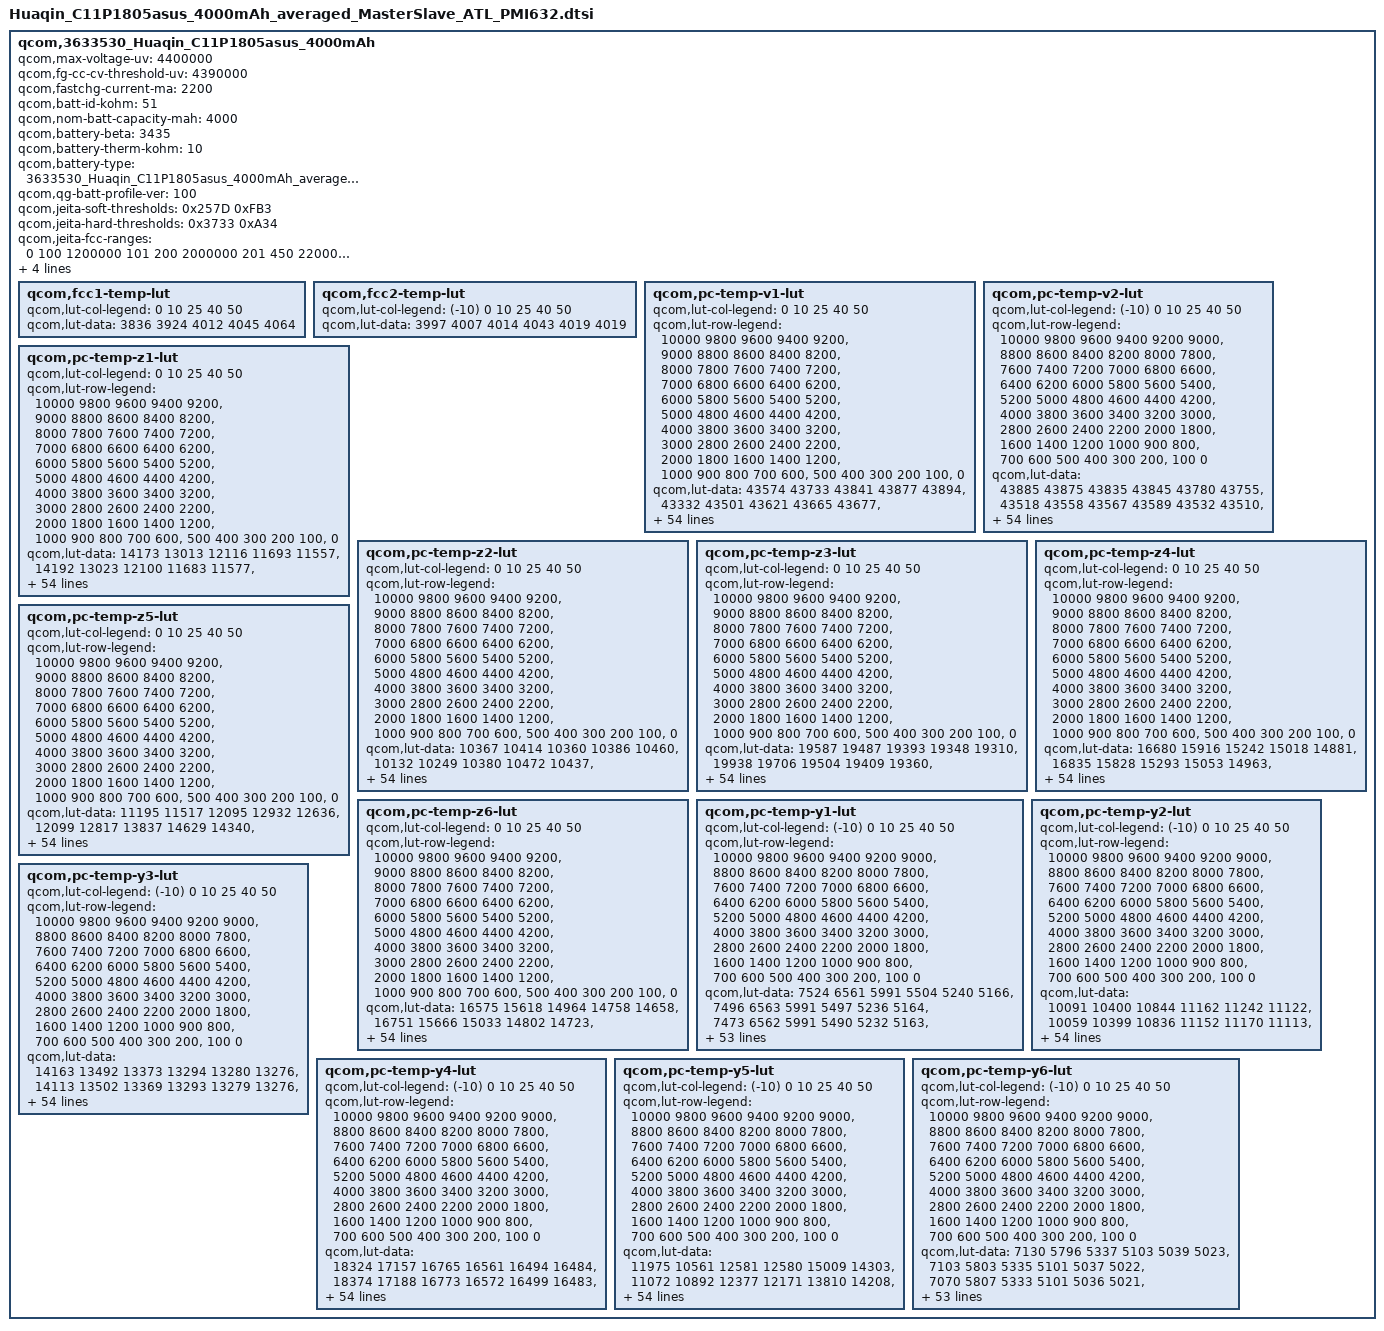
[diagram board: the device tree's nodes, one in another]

qcom,3633530_Huaqin_C11P1805asus_4000mAh {
    /* 3633530_Huaqin_C11P1805asus_4000mAh_averaged_MasterSlave_Aug22nd2018 */
    qcom,max-voltage-uv = <4400000>;
    qcom,fg-cc-cv-threshold-uv = <4390000>;
//huaqin add by tangqingyong for ZQL1830-194 jeita & step charge at 20180823 start
    qcom,fastchg-current-ma = <2200>;
//huaqin add by tangqingyong for ZQL1830-194 jeita & step charge at 20180823 end
    qcom,batt-id-kohm = <51>;
    qcom,nom-batt-capacity-mah = <4000>;
    qcom,battery-beta = <3435>;
    qcom,battery-therm-kohm = <10>;
    qcom,battery-type = "3633530_Huaqin_C11P1805asus_4000mAh_averaged_MasterSlave_Aug22nd2018";
    qcom,qg-batt-profile-ver = <100>;
//huaqin add by tangqingyong for ZQL1830-412 NTC batt-therm config start
    /* COOL = 15 DegC, WARM = 45 DegC */
    qcom,jeita-soft-thresholds = <0x257D 0xFB3>;
    /* COLD = 0 DegC, HOT = 60 DegC */
    qcom,jeita-hard-thresholds = <0x3733 0xA34>;
//huaqin add by tangqingyong for ZQL1830-412 NTC batt-therm config end
//huaqin add by tangqingyong for ZQL1830-194 jeita & step charge at 20180823 start
       qcom,jeita-fcc-ranges = <0   100  1200000
                               101  200  2000000
                               201  450  2200000
                               451  600  1400000>;
       qcom,jeita-fv-ranges = <0   100  4400000
                               101 200  4400000
                               201 450  4400000
                               451 600  4100000>;

       qcom,step-chg-ranges = <3500000  4250000  2200000
                               4251000  4400000  2000000>;
//huaqin add by tangqingyong for ZQL1830-194 jeita & step charge at 20180823 end

	qcom,fcc1-temp-lut {
		qcom,lut-col-legend = <0 10 25 40 50>;
		qcom,lut-data = <3836 3924 4012 4045 4064>;
	};

	qcom,fcc2-temp-lut {
		qcom,lut-col-legend = <(-10) 0 10 25 40 50>;
		qcom,lut-data = <3997 4007 4014 4043 4019 4019>;
	};

	qcom,pc-temp-v1-lut {
		qcom,lut-col-legend = <0 10 25 40 50>;
		qcom,lut-row-legend = <10000 9800 9600 9400 9200>,
			<9000 8800 8600 8400 8200>,
			<8000 7800 7600 7400 7200>,
			<7000 6800 6600 6400 6200>,
			<6000 5800 5600 5400 5200>,
			<5000 4800 4600 4400 4200>,
			<4000 3800 3600 3400 3200>,
			<3000 2800 2600 2400 2200>,
			<2000 1800 1600 1400 1200>,
			<1000 900 800 700 600>,
			<500 400 300 200 100>,
			<0>;
		qcom,lut-data = <43574 43733 43841 43877 43894>,
			<43332 43501 43621 43665 43677>,
			<43092 43267 43393 43447 43460>,
			<42855 43030 43162 43226 43242>,
			<42623 42795 42929 42996 43016>,
			<42396 42560 42694 42761 42783>,
			<42173 42328 42459 42528 42550>,
			<41954 42101 42224 42294 42316>,
			<41739 41879 41993 42064 42084>,
			<41531 41662 41766 41834 41857>,
			<41329 41449 41544 41607 41632>,
			<41134 41241 41329 41386 41410>,
			<40952 41044 41119 41168 41189>,
			<40767 40860 40914 40959 40975>,
			<40549 40674 40710 40756 40769>,
			<40290 40459 40509 40557 40571>,
			<40060 40224 40305 40360 40377>,
			<39899 40025 40109 40166 40188>,
			<39767 39877 39940 39988 40008>,
			<39637 39743 39805 39836 39847>,
			<39505 39591 39656 39685 39689>,
			<39372 39426 39431 39486 39497>,
			<39232 39249 39166 39243 39263>,
			<39086 39038 38979 39038 39053>,
			<38945 38831 38851 38884 38892>,
			<38810 38704 38740 38753 38754>,
			<38684 38624 38634 38636 38633>,
			<38584 38555 38536 38531 38528>,
			<38502 38481 38447 38436 38432>,
			<38433 38410 38365 38347 38338>,
			<38375 38348 38294 38267 38254>,
			<38324 38291 38233 38195 38178>,
			<38282 38241 38181 38129 38110>,
			<38249 38200 38133 38070 38047>,
			<38219 38166 38092 38023 37995>,
			<38189 38130 38051 37975 37943>,
			<38159 38098 38012 37921 37879>,
			<38120 38059 37971 37862 37804>,
			<38055 37994 37909 37791 37724>,
			<37968 37894 37812 37704 37638>,
			<37867 37784 37698 37604 37540>,
			<37740 37664 37580 37488 37421>,
			<37596 37528 37446 37353 37282>,
			<37432 37361 37285 37195 37125>,
			<37314 37230 37148 37061 36997>,
			<37224 37148 37070 36981 36924>,
			<37198 37126 37048 36964 36903>,
			<37174 37104 37030 36948 36888>,
			<37148 37086 37016 36929 36869>,
			<37076 37017 36935 36839 36747>,
			<36777 36707 36620 36519 36411>,
			<36307 36244 36161 36061 35947>,
			<35703 35642 35560 35466 35346>,
			<34872 34814 34734 34647 34514>,
			<33541 33493 33421 33359 33194>,
			<30000 30000 30000 30000 30000>;
	};

	qcom,pc-temp-v2-lut {
		qcom,lut-col-legend = <(-10) 0 10 25 40 50>;
		qcom,lut-row-legend = <10000 9800 9600 9400 9200 9000>,
			<8800 8600 8400 8200 8000 7800>,
			<7600 7400 7200 7000 6800 6600>,
			<6400 6200 6000 5800 5600 5400>,
			<5200 5000 4800 4600 4400 4200>,
			<4000 3800 3600 3400 3200 3000>,
			<2800 2600 2400 2200 2000 1800>,
			<1600 1400 1200 1000 900 800>,
			<700 600 500 400 300 200>,
			<100 0>;
		qcom,lut-data = <43885 43875 43835 43845 43780 43755>,
			<43518 43558 43567 43589 43532 43510>,
			<43181 43263 43307 43339 43289 43271>,
			<42878 42991 43057 43098 43051 43035>,
			<42602 42743 42818 42864 42819 42805>,
			<42355 42502 42582 42632 42589 42576>,
			<42150 42259 42348 42399 42358 42344>,
			<41958 42021 42117 42168 42128 42113>,
			<41715 41789 41890 41938 41900 41885>,
			<41400 41562 41667 41710 41673 41658>,
			<41166 41346 41447 41484 41450 41435>,
			<41073 41150 41232 41260 41229 41218>,
			<41001 40962 41020 41040 41012 41004>,
			<40801 40765 40820 40835 40807 40797>,
			<40290 40560 40630 40641 40612 40595>,
			<39838 40335 40430 40442 40417 40399>,
			<39616 40048 40205 40226 40213 40207>,
			<39446 39751 39969 40017 40015 40023>,
			<39273 39530 39748 39843 39841 39850>,
			<39100 39361 39534 39690 39691 39690>,
			<38932 39197 39332 39511 39520 39511>,
			<38763 39019 39136 39269 39289 39279>,
			<38603 38845 38955 39028 39048 39040>,
			<38470 38693 38800 38849 38866 38859>,
			<38356 38558 38663 38699 38715 38711>,
			<38264 38433 38539 38571 38586 38583>,
			<38192 38313 38426 38459 38474 38471>,
			<38130 38202 38322 38359 38373 38369>,
			<38072 38109 38227 38265 38279 38275>,
			<38018 38028 38138 38179 38191 38186>,
			<37965 37964 38057 38099 38112 38107>,
			<37912 37915 37979 38023 38041 38035>,
			<37860 37872 37907 37951 37974 37966>,
			<37806 37829 37846 37886 37906 37896>,
			<37754 37787 37795 37826 37839 37825>,
			<37699 37741 37746 37762 37761 37739>,
			<37638 37687 37700 37694 37666 37626>,
			<37572 37628 37654 37622 37566 37508>,
			<37499 37563 37598 37551 37479 37412>,
			<37420 37492 37532 37476 37399 37328>,
			<37338 37411 37452 37390 37313 37238>,
			<37255 37310 37340 37288 37214 37136>,
			<37171 37192 37209 37165 37097 37016>,
			<37087 37059 37060 37016 36947 36868>,
			<36995 36941 36947 36910 36845 36785>,
			<36896 36862 36889 36880 36820 36757>,
			<36843 36822 36875 36866 36805 36744>,
			<36779 36779 36846 36844 36783 36719>,
			<36696 36719 36802 36792 36744 36672>,
			<36552 36599 36668 36612 36613 36462>,
			<36285 36312 36317 36213 36240 36045>,
			<35851 35825 35780 35648 35724 35497>,
			<35215 35160 35073 34914 35049 34778>,
			<34285 34229 34083 33807 34101 33741>,
			<32726 32699 32527 32534 32677 32295>,
			<26800 26533 26564 26630 28170 27182>;
	};

	qcom,pc-temp-z1-lut {
		qcom,lut-col-legend = <0 10 25 40 50>;
		qcom,lut-row-legend = <10000 9800 9600 9400 9200>,
			<9000 8800 8600 8400 8200>,
			<8000 7800 7600 7400 7200>,
			<7000 6800 6600 6400 6200>,
			<6000 5800 5600 5400 5200>,
			<5000 4800 4600 4400 4200>,
			<4000 3800 3600 3400 3200>,
			<3000 2800 2600 2400 2200>,
			<2000 1800 1600 1400 1200>,
			<1000 900 800 700 600>,
			<500 400 300 200 100>,
			<0>;
		qcom,lut-data = <14173 13013 12116 11693 11557>,
			<14192 13023 12100 11683 11577>,
			<14157 13023 12091 11679 11572>,
			<14143 13011 12083 11677 11569>,
			<14171 13000 12075 11673 11567>,
			<14210 12995 12067 11669 11565>,
			<14215 12993 12062 11666 11563>,
			<14187 12993 12059 11663 11562>,
			<14168 12991 12056 11661 11561>,
			<14176 12988 12052 11660 11560>,
			<14190 12987 12048 11659 11559>,
			<14195 12988 12044 11657 11558>,
			<14201 12990 12040 11656 11558>,
			<14216 12982 12037 11655 11557>,
			<14215 12971 12034 11654 11558>,
			<14184 12960 12032 11654 11558>,
			<14156 12945 12028 11653 11559>,
			<14159 12940 12025 11653 11559>,
			<14166 12943 12024 11653 11559>,
			<14167 12949 12026 11652 11559>,
			<14167 12957 12029 11652 11560>,
			<14170 12971 12032 11653 11562>,
			<14177 12984 12036 11656 11565>,
			<14186 12991 12041 11659 11568>,
			<14192 12995 12047 11662 11571>,
			<14195 12997 12052 11665 11574>,
			<14199 13002 12058 11668 11576>,
			<14205 13006 12063 11671 11578>,
			<14221 13008 12067 11674 11580>,
			<14231 13010 12071 11679 11582>,
			<14222 13012 12075 11685 11584>,
			<14204 13017 12079 11687 11586>,
			<14198 13021 12082 11688 11591>,
			<14201 13024 12085 11690 11594>,
			<14206 13027 12088 11693 11596>,
			<14211 13031 12092 11696 11599>,
			<14220 13035 12096 11698 11602>,
			<14227 13040 12101 11700 11606>,
			<14231 13044 12106 11703 11609>,
			<14234 13050 12111 11706 11611>,
			<14232 13053 12115 11708 11612>,
			<14220 13054 12119 11710 11614>,
			<14211 13053 12122 11712 11616>,
			<14211 13045 12125 11713 11617>,
			<14176 13044 12127 11716 11618>,
			<14164 13049 12129 11717 11618>,
			<14170 13027 12127 11716 11619>,
			<14159 13046 12126 11718 11619>,
			<14156 13032 12127 11718 11621>,
			<14170 13045 12136 11722 11624>,
			<14176 13061 12145 11726 11630>,
			<14198 13065 12153 11734 11636>,
			<14230 13098 12167 11742 11645>,
			<14242 13139 12189 11757 11656>,
			<14242 13139 12189 11757 11656>,
			<14242 13139 12189 11757 11656>;
	};

	qcom,pc-temp-z2-lut {
		qcom,lut-col-legend = <0 10 25 40 50>;
		qcom,lut-row-legend = <10000 9800 9600 9400 9200>,
			<9000 8800 8600 8400 8200>,
			<8000 7800 7600 7400 7200>,
			<7000 6800 6600 6400 6200>,
			<6000 5800 5600 5400 5200>,
			<5000 4800 4600 4400 4200>,
			<4000 3800 3600 3400 3200>,
			<3000 2800 2600 2400 2200>,
			<2000 1800 1600 1400 1200>,
			<1000 900 800 700 600>,
			<500 400 300 200 100>,
			<0>;
		qcom,lut-data = <10367 10414 10360 10386 10460>,
			<10132 10249 10380 10472 10437>,
			<10078 10181 10385 10539 10525>,
			<10058 10152 10392 10569 10579>,
			<10055 10139 10406 10571 10610>,
			<10060 10144 10419 10573 10634>,
			<10070 10162 10427 10576 10641>,
			<10087 10183 10432 10581 10643>,
			<10106 10208 10434 10582 10643>,
			<10113 10232 10448 10593 10577>,
			<10116 10248 10467 10614 10429>,
			<10123 10261 10479 10616 10382>,
			<10151 10269 10490 10600 10402>,
			<10178 10284 10491 10584 10416>,
			<10173 10300 10477 10560 10408>,
			<10133 10305 10462 10523 10388>,
			<10107 10303 10473 10482 10378>,
			<10137 10307 10495 10428 10387>,
			<10211 10351 10500 10403 10400>,
			<10252 10402 10490 10402 10402>,
			<10249 10386 10476 10404 10405>,
			<10228 10280 10445 10450 10439>,
			<10188 10203 10409 10585 10594>,
			<10122 10186 10412 10647 10688>,
			<10086 10177 10467 10626 10643>,
			<10078 10182 10508 10596 10560>,
			<10073 10214 10492 10577 10501>,
			<10073 10237 10451 10561 10449>,
			<10080 10236 10425 10545 10430>,
			<10090 10234 10408 10515 10440>,
			<10103 10234 10400 10490 10458>,
			<10121 10233 10407 10491 10457>,
			<10143 10233 10424 10498 10434>,
			<10193 10246 10436 10508 10434>,
			<10248 10275 10444 10522 10463>,
			<10264 10290 10452 10541 10496>,
			<10264 10294 10461 10577 10537>,
			<10260 10296 10472 10639 10593>,
			<10257 10298 10493 10685 10606>,
			<10256 10306 10543 10722 10602>,
			<10258 10314 10576 10741 10611>,
			<10263 10325 10577 10732 10635>,
			<10278 10337 10577 10718 10655>,
			<10312 10346 10588 10727 10645>,
			<10136 10463 10610 10710 10609>,
			<10101 10516 10640 10703 10521>,
			<10237 10634 10608 10588 10543>,
			<10266 10650 10597 10589 10493>,
			<10207 10742 10717 10586 10561>,
			<9952 10727 10731 10736 10532>,
			<9962 10808 10846 10677 10395>,
			<9807 10881 10782 10567 10286>,
			<9730 10838 10768 10547 10337>,
			<9584 10805 10695 10420 10263>,
			<9584 10805 10695 10420 10263>,
			<9584 10805 10695 10420 10263>;
	};

	qcom,pc-temp-z3-lut {
		qcom,lut-col-legend = <0 10 25 40 50>;
		qcom,lut-row-legend = <10000 9800 9600 9400 9200>,
			<9000 8800 8600 8400 8200>,
			<8000 7800 7600 7400 7200>,
			<7000 6800 6600 6400 6200>,
			<6000 5800 5600 5400 5200>,
			<5000 4800 4600 4400 4200>,
			<4000 3800 3600 3400 3200>,
			<3000 2800 2600 2400 2200>,
			<2000 1800 1600 1400 1200>,
			<1000 900 800 700 600>,
			<500 400 300 200 100>,
			<0>;
		qcom,lut-data = <19587 19487 19393 19348 19310>,
			<19938 19706 19504 19409 19360>,
			<20060 19791 19564 19438 19388>,
			<20118 19830 19577 19448 19405>,
			<20136 19848 19567 19446 19404>,
			<20139 19844 19551 19441 19402>,
			<20128 19825 19540 19435 19400>,
			<20103 19802 19530 19425 19398>,
			<20073 19774 19524 19418 19395>,
			<20054 19748 19517 19415 19386>,
			<20037 19733 19509 19414 19370>,
			<20015 19721 19498 19408 19363>,
			<19974 19714 19487 19395 19362>,
			<19939 19698 19482 19387 19361>,
			<19948 19678 19481 19388 19357>,
			<19998 19675 19480 19389 19351>,
			<20031 19679 19470 19385 19348>,
			<19996 19679 19453 19370 19347>,
			<19910 19653 19448 19361 19346>,
			<19863 19621 19450 19360 19346>,
			<19868 19634 19455 19360 19346>,
			<19894 19712 19485 19365 19349>,
			<19949 19778 19530 19384 19365>,
			<20044 19811 19538 19400 19382>,
			<20107 19832 19520 19412 19394>,
			<20136 19828 19507 19422 19403>,
			<20154 19785 19513 19426 19401>,
			<20156 19753 19525 19429 19389>,
			<20143 19754 19530 19429 19382>,
			<20125 19758 19532 19424 19383>,
			<20103 19761 19533 19417 19385>,
			<20072 19762 19527 19412 19382>,
			<20038 19763 19515 19407 19375>,
			<19984 19751 19509 19404 19370>,
			<19928 19728 19506 19402 19365>,
			<19905 19719 19503 19400 19361>,
			<19894 19720 19501 19399 19360>,
			<19893 19721 19498 19399 19361>,
			<19913 19723 19497 19398 19361>,
			<19939 19726 19497 19396 19360>,
			<19936 19725 19496 19393 19360>,
			<19907 19706 19487 19388 19361>,
			<19879 19689 19475 19383 19364>,
			<19849 19683 19469 19385 19368>,
			<19491 19616 19465 19384 19365>,
			<19446 19588 19449 19378 19346>,
			<19394 19527 19446 19356 19349>,
			<19395 19525 19448 19362 19347>,
			<19394 19496 19403 19352 19329>,
			<19317 19505 19422 19343 19351>,
			<19315 19481 19403 19346 19362>,
			<19323 19453 19417 19348 19367>,
			<19324 19450 19413 19348 19343>,
			<19333 19416 19415 19361 19343>,
			<19333 19416 19415 19361 19343>,
			<19333 19416 19415 19361 19343>;
	};

	qcom,pc-temp-z4-lut {
		qcom,lut-col-legend = <0 10 25 40 50>;
		qcom,lut-row-legend = <10000 9800 9600 9400 9200>,
			<9000 8800 8600 8400 8200>,
			<8000 7800 7600 7400 7200>,
			<7000 6800 6600 6400 6200>,
			<6000 5800 5600 5400 5200>,
			<5000 4800 4600 4400 4200>,
			<4000 3800 3600 3400 3200>,
			<3000 2800 2600 2400 2200>,
			<2000 1800 1600 1400 1200>,
			<1000 900 800 700 600>,
			<500 400 300 200 100>,
			<0>;
		qcom,lut-data = <16680 15916 15242 15018 14881>,
			<16835 15828 15293 15053 14963>,
			<16600 15720 15258 15027 14942>,
			<16339 15579 15209 14992 14907>,
			<16176 15440 15127 14961 14886>,
			<16046 15329 15062 14931 14871>,
			<15930 15240 15035 14915 14860>,
			<15817 15198 15016 14905 14849>,
			<15720 15178 14995 14895 14840>,
			<15645 15167 14972 14880 14837>,
			<15585 15156 14954 14864 14835>,
			<15564 15144 14941 14854 14831>,
			<15573 15136 14928 14848 14819>,
			<15582 15136 14917 14840 14805>,
			<15572 15138 14907 14824 14795>,
			<15526 15136 14899 14806 14786>,
			<15490 15123 14892 14799 14775>,
			<15487 15109 14885 14795 14762>,
			<15491 15095 14873 14791 14751>,
			<15491 15080 14847 14780 14742>,
			<15452 15056 14829 14771 14736>,
			<15395 15022 14921 14812 14757>,
			<15347 15008 15100 14947 14857>,
			<15286 15091 15149 15009 14917>,
			<15262 15218 15130 14985 14902>,
			<15268 15241 15099 14948 14877>,
			<15279 15208 15054 14916 14860>,
			<15283 15166 14997 14886 14848>,
			<15285 15125 14955 14861 14834>,
			<15285 15082 14923 14841 14815>,
			<15278 15051 14898 14824 14795>,
			<15265 15024 14881 14807 14781>,
			<15262 15008 14868 14793 14769>,
			<15281 15006 14856 14783 14761>,
			<15306 15005 14845 14776 14757>,
			<15310 15003 14840 14773 14754>,
			<15298 14990 14842 14786 14767>,
			<15285 14979 14846 14817 14802>,
			<15250 14981 14855 14828 14814>,
			<15204 14988 14876 14831 14809>,
			<15195 14992 14890 14832 14802>,
			<15207 14990 14884 14824 14791>,
			<15213 14987 14877 14812 14779>,
			<15212 14979 14882 14816 14785>,
			<15408 14971 14867 14813 14785>,
			<15416 14951 14831 14788 14769>,
			<15455 14988 14803 14779 14744>,
			<15437 14984 14772 14738 14713>,
			<15426 14989 14793 14722 14704>,
			<15506 14985 14800 14758 14716>,
			<15530 15048 14852 14777 14720>,
			<15541 15080 14839 14780 14719>,
			<15555 15090 14846 14779 14740>,
			<15558 15136 14848 14769 14743>,
			<15558 15136 14848 14769 14743>,
			<15558 15136 14848 14769 14743>;
	};

	qcom,pc-temp-z5-lut {
		qcom,lut-col-legend = <0 10 25 40 50>;
		qcom,lut-row-legend = <10000 9800 9600 9400 9200>,
			<9000 8800 8600 8400 8200>,
			<8000 7800 7600 7400 7200>,
			<7000 6800 6600 6400 6200>,
			<6000 5800 5600 5400 5200>,
			<5000 4800 4600 4400 4200>,
			<4000 3800 3600 3400 3200>,
			<3000 2800 2600 2400 2200>,
			<2000 1800 1600 1400 1200>,
			<1000 900 800 700 600>,
			<500 400 300 200 100>,
			<0>;
		qcom,lut-data = <11195 11517 12095 12932 12636>,
			<12099 12817 13837 14629 14340>,
			<12534 13484 14872 15530 15630>,
			<12751 13896 15316 16042 16512>,
			<12790 14231 15508 16389 16823>,
			<12780 14553 15576 16610 17027>,
			<12777 14810 15532 16596 17128>,
			<12821 14846 15516 16319 17197>,
			<12893 14662 15576 16122 17239>,
			<12970 14426 15668 16256 16820>,
			<13054 14298 15673 16455 15816>,
			<13074 14249 15495 16350 15477>,
			<12909 14267 15258 15795 15659>,
			<12734 14122 15172 15487 15815>,
			<12815 13899 15112 15654 15666>,
			<13235 13905 15022 15856 15357>,
			<13524 14049 14830 15712 15310>,
			<13327 14109 14603 15144 15636>,
			<12870 13936 14588 14876 16052>,
			<12687 13732 15080 15163 16481>,
			<12910 14371 15922 15541 16853>,
			<13351 17115 18083 15553 16684>,
			<14160 19380 20786 15288 15636>,
			<15688 20441 20843 15113 15017>,
			<16945 21150 17535 14988 15245>,
			<17785 20777 15083 14918 15574>,
			<18381 18038 15219 15198 15611>,
			<18432 16048 15700 15860 15499>,
			<17957 16148 16316 16380 15461>,
			<17368 16477 17301 16695 16159>,
			<16963 16856 18072 17022 17083>,
			<16563 17554 18345 17502 17493>,
			<16121 18079 18532 18124 17822>,
			<15347 17846 18887 18854 18155>,
			<14565 17268 19556 19917 18633>,
			<14275 17079 20030 20638 19013>,
			<14241 17330 20174 20581 18858>,
			<14320 17728 20249 20312 18180>,
			<14970 18269 20220 19978 17796>,
			<15842 18974 20121 19222 17510>,
			<15906 19171 19942 18366 17311>,
			<15281 18015 19064 17687 17462>,
			<14892 17269 17891 17177 17706>,
			<14771 17319 17278 16856 17559>,
			<12445 15997 17457 16661 16744>,
			<12262 15462 16874 16654 15402>,
			<11694 13792 17169 15298 16157>,
			<11720 13801 17823 16647 17308>,
			<11729 13299 14816 16704 16303>,
			<11229 13407 15761 14633 16452>,
			<11220 13011 13936 13766 16217>,
			<11217 12492 14126 13551 16144>,
			<11153 12355 13850 13308 13820>,
			<11120 11936 13655 13660 13532>,
			<11120 11936 13655 13660 13532>,
			<11120 11936 13655 13660 13532>;
	};

	qcom,pc-temp-z6-lut {
		qcom,lut-col-legend = <0 10 25 40 50>;
		qcom,lut-row-legend = <10000 9800 9600 9400 9200>,
			<9000 8800 8600 8400 8200>,
			<8000 7800 7600 7400 7200>,
			<7000 6800 6600 6400 6200>,
			<6000 5800 5600 5400 5200>,
			<5000 4800 4600 4400 4200>,
			<4000 3800 3600 3400 3200>,
			<3000 2800 2600 2400 2200>,
			<2000 1800 1600 1400 1200>,
			<1000 900 800 700 600>,
			<500 400 300 200 100>,
			<0>;
		qcom,lut-data = <16575 15618 14964 14758 14658>,
			<16751 15666 15033 14802 14723>,
			<16675 15664 15043 14804 14724>,
			<16581 15609 15037 14798 14720>,
			<16508 15538 14997 14784 14713>,
			<16440 15477 14955 14767 14704>,
			<16368 15421 14934 14756 14698>,
			<16285 15384 14920 14746 14692>,
			<16210 15358 14907 14737 14686>,
			<16159 15338 14893 14729 14679>,
			<16118 15323 14879 14721 14670>,
			<16091 15311 14867 14713 14663>,
			<16076 15301 14855 14704 14657>,
			<16070 15289 14847 14696 14651>,
			<16071 15277 14842 14689 14644>,
			<16063 15268 14837 14682 14637>,
			<16050 15261 14827 14675 14631>,
			<16026 15251 14815 14666 14624>,
			<15989 15231 14806 14659 14619>,
			<15966 15212 14797 14653 14616>,
			<15951 15213 14793 14650 14613>,
			<15943 15237 14847 14672 14624>,
			<15950 15272 14950 14743 14679>,
			<15981 15333 14976 14776 14713>,
			<16011 15398 14961 14771 14711>,
			<16033 15406 14942 14762 14707>,
			<16051 15373 14926 14753 14700>,
			<16060 15341 14909 14741 14689>,
			<16059 15324 14895 14730 14678>,
			<16053 15312 14883 14718 14671>,
			<16037 15304 14873 14708 14663>,
			<16014 15297 14862 14698 14655>,
			<15997 15292 14851 14690 14647>,
			<15982 15285 14844 14684 14640>,
			<15971 15278 14838 14679 14636>,
			<15965 15275 14835 14677 14633>,
			<15962 15273 14836 14683 14639>,
			<15960 15273 14837 14696 14654>,
			<15962 15277 14841 14701 14659>,
			<15966 15286 14852 14701 14657>,
			<15964 15290 14859 14700 14654>,
			<15956 15284 14852 14695 14651>,
			<15949 15278 14844 14687 14647>,
			<15943 15273 14844 14690 14652>,
			<15859 15241 14838 14689 14650>,
			<15839 15224 14814 14675 14634>,
			<15834 15204 14801 14660 14624>,
			<15828 15211 14789 14645 14610>,
			<15828 15194 14775 14632 14596>,
			<15828 15201 14789 14644 14614>,
			<15855 15229 14804 14655 14624>,
			<15882 15232 14808 14660 14627>,
			<15911 15249 14813 14661 14626>,
			<15936 15270 14821 14667 14630>,
			<15936 15270 14821 14667 14630>,
			<15936 15270 14821 14667 14630>;
	};

	qcom,pc-temp-y1-lut {
		qcom,lut-col-legend = <(-10) 0 10 25 40 50>;
		qcom,lut-row-legend = <10000 9800 9600 9400 9200 9000>,
			<8800 8600 8400 8200 8000 7800>,
			<7600 7400 7200 7000 6800 6600>,
			<6400 6200 6000 5800 5600 5400>,
			<5200 5000 4800 4600 4400 4200>,
			<4000 3800 3600 3400 3200 3000>,
			<2800 2600 2400 2200 2000 1800>,
			<1600 1400 1200 1000 900 800>,
			<700 600 500 400 300 200>,
			<100 0>;
		qcom,lut-data = <7524 6561 5991 5504 5240 5166>,
			<7496 6563 5991 5497 5236 5164>,
			<7473 6562 5991 5490 5232 5163>,
			<7455 6559 5989 5483 5228 5161>,
			<7443 6556 5986 5476 5225 5159>,
			<7436 6555 5983 5469 5222 5158>,
			<7438 6555 5975 5462 5220 5158>,
			<7443 6554 5967 5455 5218 5157>,
			<7442 6550 5966 5450 5216 5156>,
			<7439 6541 5968 5445 5212 5154>,
			<7436 6536 5968 5442 5210 5153>,
			<7431 6538 5967 5441 5210 5153>,
			<7427 6542 5963 5440 5210 5153>,
			<7426 6541 5957 5438 5209 5152>,
			<7424 6538 5947 5431 5205 5150>,
			<7423 6536 5942 5426 5203 5149>,
			<7420 6545 5945 5423 5204 5149>,
			<7415 6556 5948 5421 5205 5150>,
			<7412 6558 5949 5421 5206 5151>,
			<7406 6555 5949 5422 5205 5152>,
			<7401 6555 5949 5422 5205 5153>,
			<7399 6562 5951 5423 5207 5154>,
			<7397 6569 5954 5423 5208 5154>,
			<7395 6568 5955 5425 5209 5154>,
			<7386 6552 5956 5427 5209 5154>,
			<7377 6542 5957 5429 5210 5155>,
			<7375 6543 5959 5430 5212 5157>,
			<7372 6544 5960 5432 5214 5159>,
			<7371 6544 5961 5434 5215 5160>,
			<7369 6541 5963 5438 5217 5160>,
			<7366 6538 5964 5442 5220 5161>,
			<7363 6538 5963 5448 5222 5164>,
			<7358 6538 5963 5454 5225 5167>,
			<7352 6540 5964 5457 5227 5170>,
			<7343 6545 5969 5460 5230 5172>,
			<7333 6547 5972 5463 5234 5174>,
			<7323 6543 5972 5465 5237 5176>,
			<7313 6537 5971 5468 5240 5178>,
			<7309 6534 5972 5470 5241 5180>,
			<7310 6529 5973 5472 5241 5182>,
			<7312 6525 5973 5475 5242 5183>,
			<7310 6522 5972 5479 5243 5184>,
			<7303 6521 5974 5481 5245 5184>,
			<7294 6523 5993 5482 5249 5186>,
			<7290 6533 5985 5486 5253 5188>,
			<7327 6545 5982 5490 5252 5191>,
			<7333 6540 5984 5491 5256 5192>,
			<7323 6546 5976 5493 5255 5190>,
			<7323 6543 5983 5494 5256 5189>,
			<7327 6530 5993 5495 5253 5191>,
			<7336 6542 5998 5503 5258 5194>,
			<7339 6543 6006 5511 5264 5198>,
			<7346 6555 6020 5523 5270 5207>,
			<7352 6578 6038 5541 5281 5218>,
			<7352 6578 6038 5541 5281 5218>,
			<7352 6578 6038 5541 5281 5218>;
	};

	qcom,pc-temp-y2-lut {
		qcom,lut-col-legend = <(-10) 0 10 25 40 50>;
		qcom,lut-row-legend = <10000 9800 9600 9400 9200 9000>,
			<8800 8600 8400 8200 8000 7800>,
			<7600 7400 7200 7000 6800 6600>,
			<6400 6200 6000 5800 5600 5400>,
			<5200 5000 4800 4600 4400 4200>,
			<4000 3800 3600 3400 3200 3000>,
			<2800 2600 2400 2200 2000 1800>,
			<1600 1400 1200 1000 900 800>,
			<700 600 500 400 300 200>,
			<100 0>;
		qcom,lut-data = <10091 10400 10844 11162 11242 11122>,
			<10059 10399 10836 11152 11170 11113>,
			<10046 10403 10824 11142 11117 11096>,
			<10046 10408 10809 11133 11082 11075>,
			<10056 10415 10794 11123 11059 11053>,
			<10072 10419 10782 11111 11047 11034>,
			<10103 10425 10769 11098 11052 11012>,
			<10154 10431 10757 11085 11067 10993>,
			<10227 10432 10753 11079 11078 10985>,
			<10363 10425 10747 11079 11101 10971>,
			<10440 10421 10744 11082 11116 10964>,
			<10406 10463 10745 11089 11106 11001>,
			<10355 10537 10747 11095 11091 11052>,
			<10332 10575 10752 11085 11093 11050>,
			<10215 10606 10766 11050 11104 11004>,
			<10112 10625 10781 11035 11120 10987>,
			<9942 10636 10796 11079 11149 11001>,
			<9714 10650 10813 11134 11186 11020>,
			<9674 10673 10831 11153 11221 11076>,
			<9670 10713 10848 11165 11269 11200>,
			<9668 10756 10872 11167 11300 11256>,
			<9666 10799 10926 11151 11293 11190>,
			<9664 10843 10991 11142 11271 11108>,
			<9663 10884 11029 11187 11247 11103>,
			<9662 10923 11053 11287 11195 11125>,
			<9661 10948 11077 11325 11178 11147>,
			<9660 10966 11108 11325 11236 11165>,
			<9659 10984 11136 11323 11304 11183>,
			<9658 11019 11149 11318 11328 11199>,
			<9657 11094 11158 11302 11351 11211>,
			<9657 11126 11160 11296 11364 11237>,
			<9656 10937 11151 11311 11374 11329>,
			<9656 10583 11138 11325 11388 11424>,
			<9655 10435 11135 11316 11411 11442>,
			<9655 10372 11133 11294 11440 11443>,
			<9654 10297 11129 11288 11445 11430>,
			<9654 10012 11110 11295 11414 11333>,
			<9654 9737 11078 11301 11374 11234>,
			<9654 9696 11037 11306 11348 11234>,
			<9653 9680 10983 11315 11329 11262>,
			<9653 9672 10957 11316 11333 11273>,
			<9653 9668 10952 11291 11379 11261>,
			<9653 9664 10940 11284 11378 11248>,
			<9653 9661 10853 11328 11304 11268>,
			<9653 9658 10775 11284 11274 11123>,
			<9653 9658 10771 11260 11272 11059>,
			<9653 9657 10719 11224 11252 11081>,
			<9653 9656 10688 11202 11220 11078>,
			<9653 9655 10642 11171 11148 11065>,
			<9653 9654 10593 11191 11136 10976>,
			<9652 9654 10520 11173 11161 10962>,
			<9652 9653 10431 11104 11086 10896>,
			<9652 9652 10337 10977 11015 10832>,
			<9651 9652 10241 10851 10890 10696>,
			<9651 9652 10241 10851 10890 10696>,
			<9651 9652 10241 10851 10890 10696>;
	};

	qcom,pc-temp-y3-lut {
		qcom,lut-col-legend = <(-10) 0 10 25 40 50>;
		qcom,lut-row-legend = <10000 9800 9600 9400 9200 9000>,
			<8800 8600 8400 8200 8000 7800>,
			<7600 7400 7200 7000 6800 6600>,
			<6400 6200 6000 5800 5600 5400>,
			<5200 5000 4800 4600 4400 4200>,
			<4000 3800 3600 3400 3200 3000>,
			<2800 2600 2400 2200 2000 1800>,
			<1600 1400 1200 1000 900 800>,
			<700 600 500 400 300 200>,
			<100 0>;
		qcom,lut-data = <14163 13492 13373 13294 13280 13276>,
			<14113 13502 13369 13293 13279 13276>,
			<14084 13516 13368 13293 13279 13277>,
			<14071 13530 13368 13293 13279 13277>,
			<14070 13542 13369 13293 13279 13277>,
			<14075 13549 13369 13294 13280 13278>,
			<14131 13552 13371 13300 13283 13278>,
			<14213 13554 13375 13307 13288 13278>,
			<14171 13559 13377 13308 13289 13278>,
			<13857 13567 13382 13307 13289 13279>,
			<13651 13573 13385 13306 13289 13279>,
			<13700 13567 13387 13304 13289 13282>,
			<13780 13555 13389 13303 13287 13286>,
			<13789 13552 13392 13305 13288 13286>,
			<13734 13551 13401 13313 13293 13285>,
			<13681 13549 13408 13317 13296 13285>,
			<13631 13538 13411 13318 13295 13285>,
			<13576 13519 13412 13319 13293 13287>,
			<13557 13504 13410 13322 13294 13289>,
			<13545 13489 13400 13328 13298 13292>,
			<13539 13475 13387 13330 13300 13293>,
			<13537 13457 13372 13325 13297 13289>,
			<13536 13437 13359 13316 13291 13282>,
			<13533 13425 13356 13308 13288 13279>,
			<13529 13416 13354 13299 13286 13278>,
			<13531 13409 13353 13296 13286 13277>,
			<13551 13399 13351 13298 13286 13278>,
			<13586 13387 13349 13300 13286 13279>,
			<13619 13372 13349 13302 13286 13279>,
			<13653 13348 13348 13305 13285 13279>,
			<13690 13337 13348 13308 13285 13280>,
			<13734 13344 13350 13308 13286 13281>,
			<13785 13356 13351 13309 13288 13282>,
			<13841 13367 13351 13309 13289 13282>,
			<13906 13380 13351 13311 13289 13282>,
			<13976 13390 13350 13311 13289 13282>,
			<14047 13390 13351 13308 13288 13281>,
			<14121 13389 13352 13307 13286 13280>,
			<14202 13397 13355 13307 13285 13279>,
			<14293 13415 13361 13306 13285 13278>,
			<14390 13438 13363 13306 13285 13277>,
			<14491 13472 13355 13307 13286 13277>,
			<14595 13517 13349 13306 13286 13277>,
			<14703 13573 13351 13300 13281 13276>,
			<14793 13669 13354 13299 13281 13278>,
			<14767 13701 13350 13303 13289 13280>,
			<14820 13742 13368 13308 13289 13288>,
			<14903 13840 13370 13315 13291 13291>,
			<15029 13942 13387 13319 13300 13297>,
			<15154 14052 13396 13314 13304 13289>,
			<15304 14212 13398 13312 13294 13285>,
			<15498 14447 13404 13314 13293 13287>,
			<15752 14773 13432 13329 13301 13296>,
			<16157 15149 13487 13349 13308 13299>,
			<16157 15149 13487 13349 13308 13299>,
			<16157 15149 13487 13349 13308 13299>;
	};

	qcom,pc-temp-y4-lut {
		qcom,lut-col-legend = <(-10) 0 10 25 40 50>;
		qcom,lut-row-legend = <10000 9800 9600 9400 9200 9000>,
			<8800 8600 8400 8200 8000 7800>,
			<7600 7400 7200 7000 6800 6600>,
			<6400 6200 6000 5800 5600 5400>,
			<5200 5000 4800 4600 4400 4200>,
			<4000 3800 3600 3400 3200 3000>,
			<2800 2600 2400 2200 2000 1800>,
			<1600 1400 1200 1000 900 800>,
			<700 600 500 400 300 200>,
			<100 0>;
		qcom,lut-data = <18324 17157 16765 16561 16494 16484>,
			<18374 17188 16773 16572 16499 16483>,
			<18397 17209 16779 16580 16503 16483>,
			<18397 17222 16784 16584 16506 16484>,
			<18379 17227 16786 16587 16508 16484>,
			<18347 17227 16787 16587 16509 16485>,
			<18176 17219 16785 16583 16508 16488>,
			<17942 17204 16783 16577 16506 16492>,
			<17981 17189 16785 16579 16507 16497>,
			<18447 17167 16794 16593 16514 16502>,
			<18777 17157 16804 16609 16523 16507>,
			<18794 17228 16814 16627 16534 16509>,
			<18766 17346 16828 16645 16547 16511>,
			<18609 17400 16859 16659 16556 16517>,
			<18063 17443 16922 16669 16563 16530>,
			<17719 17454 16955 16682 16572 16543>,
			<17775 17303 16952 16703 16585 16552>,
			<17866 17088 16942 16727 16602 16561>,
			<17850 17037 16913 16755 16624 16575>,
			<17742 17028 16830 16788 16655 16597>,
			<17618 17018 16762 16793 16669 16607>,
			<17491 16999 16728 16696 16623 16576>,
			<17373 16974 16703 16586 16555 16529>,
			<17318 16949 16687 16561 16523 16507>,
			<17289 16922 16674 16549 16504 16493>,
			<17271 16896 16669 16547 16497 16489>,
			<17259 16864 16668 16548 16499 16491>,
			<17250 16838 16669 16550 16504 16494>,
			<17249 16841 16669 16554 16510 16500>,
			<17253 16866 16670 16559 16523 16509>,
			<17258 16885 16670 16566 16536 16520>,
			<17267 16891 16660 16574 16553 16533>,
			<17278 16896 16648 16583 16567 16546>,
			<17281 16906 16647 16592 16571 16550>,
			<17283 16919 16652 16599 16572 16553>,
			<17284 16935 16660 16599 16571 16552>,
			<17283 16977 16672 16584 16543 16528>,
			<17281 17020 16685 16567 16511 16501>,
			<17281 17037 16692 16555 16506 16495>,
			<17283 17048 16696 16546 16505 16494>,
			<17286 17052 16702 16545 16505 16493>,
			<17296 17047 16710 16548 16505 16493>,
			<17316 17039 16718 16553 16506 16492>,
			<17348 17031 16723 16559 16508 16484>,
			<17393 17041 16719 16541 16495 16479>,
			<17349 17028 16728 16562 16505 16497>,
			<17348 17056 16739 16583 16523 16505>,
			<17383 17101 16787 16605 16541 16527>,
			<17419 17169 16836 16634 16564 16558>,
			<17429 17224 16852 16619 16551 16507>,
			<17414 17222 16814 16583 16502 16489>,
			<17385 17218 16828 16590 16512 16494>,
			<17389 17269 16869 16620 16517 16507>,
			<17465 17371 16970 16712 16563 16575>,
			<17465 17371 16970 16712 16563 16575>,
			<17465 17371 16970 16712 16563 16575>;
	};

	qcom,pc-temp-y5-lut {
		qcom,lut-col-legend = <(-10) 0 10 25 40 50>;
		qcom,lut-row-legend = <10000 9800 9600 9400 9200 9000>,
			<8800 8600 8400 8200 8000 7800>,
			<7600 7400 7200 7000 6800 6600>,
			<6400 6200 6000 5800 5600 5400>,
			<5200 5000 4800 4600 4400 4200>,
			<4000 3800 3600 3400 3200 3000>,
			<2800 2600 2400 2200 2000 1800>,
			<1600 1400 1200 1000 900 800>,
			<700 600 500 400 300 200>,
			<100 0>;
		qcom,lut-data = <11975 10561 12581 12580 15009 14303>,
			<11072 10892 12377 12171 13810 14208>,
			<10672 11360 12240 11925 13085 14067>,
			<10666 11855 12159 11801 12714 13900>,
			<10946 12266 12121 11756 12580 13726>,
			<11403 12484 12111 11753 12563 13562>,
			<12797 12543 12170 12133 13078 13397>,
			<14539 12587 12250 12657 13833 13220>,
			<14424 12731 12265 12676 13909 13020>,
			<12059 13087 12298 12414 13620 12767>,
			<10508 13300 12325 12144 13275 12647>,
			<11868 12883 12313 11872 12856 13041>,
			<14019 12228 12301 11659 12484 13591>,
			<14294 12460 12357 11693 12491 13559>,
			<13255 14236 12548 11917 12753 13033>,
			<12430 15393 12863 12136 12901 12669>,
			<11853 15204 14040 12282 12754 12658>,
			<11149 14802 15408 12470 12560 12773>,
			<11096 14634 15592 13090 12600 12948>,
			<11258 14374 15474 14459 12972 13216>,
			<11375 14135 15278 15386 13495 13531>,
			<11364 13709 14497 15992 14559 14006>,
			<11290 13207 13600 16357 15593 14471>,
			<11157 13129 13500 15630 15798 14612>,
			<10860 13240 13604 13855 15786 14611>,
			<10696 13352 13671 13246 15711 14612>,
			<10713 13356 13645 13501 15581 14644>,
			<10741 13142 13616 13834 15410 14608>,
			<10746 12627 13677 14256 15151 14479>,
			<10738 11626 13862 14996 14719 14331>,
			<10725 11186 14101 15427 14514 14422>,
			<10703 11336 14507 15623 14845 14707>,
			<10679 11559 14865 15789 15417 15047>,
			<10686 11734 14855 16170 15963 15428>,
			<10759 11900 14652 16912 16531 15912>,
			<10832 11943 14465 17082 16734 16138>,
			<10879 11538 14322 16566 16577 16133>,
			<10915 11128 14224 16176 16305 16085>,
			<10906 11136 14342 16044 16010 15736>,
			<10857 11199 14723 15821 15604 14894>,
			<10821 11259 14827 15641 15414 14346>,
			<10786 11321 13797 15440 15314 14067>,
			<10755 11294 12944 15071 15058 13961>,
			<10781 11157 12728 13860 13858 14070>,
			<10762 10994 12724 13720 13870 14113>,
			<10859 11188 12371 13630 14744 13399>,
			<10935 11105 13230 13700 13789 14890>,
			<10995 11241 12828 13943 13592 14803>,
			<11160 11348 13130 13974 14680 15857>,
			<11232 11500 13318 13462 15756 14780>,
			<11182 11276 13392 13621 15043 14043>,
			<11023 11227 13037 13640 14308 14351>,
			<10876 11216 13397 15629 16282 17403>,
			<10808 11212 14266 17072 17367 17560>,
			<10808 11212 14266 17072 17367 17560>,
			<10808 11212 14266 17072 17367 17560>;
	};

	qcom,pc-temp-y6-lut {
		qcom,lut-col-legend = <(-10) 0 10 25 40 50>;
		qcom,lut-row-legend = <10000 9800 9600 9400 9200 9000>,
			<8800 8600 8400 8200 8000 7800>,
			<7600 7400 7200 7000 6800 6600>,
			<6400 6200 6000 5800 5600 5400>,
			<5200 5000 4800 4600 4400 4200>,
			<4000 3800 3600 3400 3200 3000>,
			<2800 2600 2400 2200 2000 1800>,
			<1600 1400 1200 1000 900 800>,
			<700 600 500 400 300 200>,
			<100 0>;
		qcom,lut-data = <7130 5796 5337 5103 5039 5023>,
			<7103 5803 5335 5101 5037 5022>,
			<7070 5807 5333 5101 5036 5021>,
			<7037 5809 5331 5101 5036 5022>,
			<7008 5810 5328 5100 5037 5022>,
			<6992 5809 5325 5101 5037 5023>,
			<6986 5801 5322 5102 5039 5024>,
			<6981 5787 5319 5103 5042 5025>,
			<6960 5778 5319 5105 5044 5026>,
			<6890 5772 5322 5108 5046 5028>,
			<6846 5769 5325 5111 5048 5030>,
			<6877 5780 5327 5114 5050 5032>,
			<6925 5800 5330 5118 5053 5035>,
			<6899 5810 5338 5124 5056 5038>,
			<6703 5818 5358 5130 5061 5041>,
			<6556 5820 5370 5137 5066 5044>,
			<6534 5776 5371 5144 5069 5047>,
			<6521 5708 5370 5151 5073 5051>,
			<6506 5681 5361 5161 5079 5056>,
			<6484 5669 5329 5173 5091 5065>,
			<6461 5660 5300 5176 5096 5068>,
			<6436 5649 5281 5145 5080 5056>,
			<6415 5638 5266 5107 5056 5037>,
			<6412 5626 5260 5093 5045 5029>,
			<6421 5613 5257 5084 5038 5024>,
			<6435 5605 5255 5082 5035 5022>,
			<6459 5601 5256 5083 5036 5023>,
			<6492 5599 5256 5086 5038 5025>,
			<6525 5599 5258 5089 5040 5026>,
			<6559 5606 5260 5093 5043 5029>,
			<6597 5617 5262 5097 5047 5033>,
			<6639 5638 5263 5101 5053 5038>,
			<6686 5668 5263 5104 5058 5042>,
			<6734 5698 5266 5108 5060 5044>,
			<6783 5732 5271 5112 5061 5045>,
			<6834 5766 5278 5112 5061 5045>,
			<6886 5797 5286 5107 5052 5038>,
			<6940 5830 5295 5102 5042 5029>,
			<7000 5871 5305 5099 5040 5027>,
			<7066 5921 5316 5097 5040 5026>,
			<7139 5976 5324 5097 5040 5025>,
			<7218 6033 5329 5099 5041 5025>,
			<7302 6098 5338 5101 5042 5025>,
			<7388 6176 5364 5099 5039 5023>,
			<7466 6286 5374 5094 5035 5022>,
			<7447 6307 5372 5103 5044 5030>,
			<7489 6354 5397 5113 5050 5037>,
			<7554 6456 5427 5125 5057 5046>,
			<7658 6560 5466 5137 5069 5059>,
			<7758 6659 5494 5128 5068 5039>,
			<7867 6794 5512 5120 5048 5031>,
			<8008 6978 5561 5124 5051 5035>,
			<8210 7245 5654 5145 5059 5046>,
			<8554 7560 5803 5192 5078 5070>,
			<8554 7560 5803 5192 5078 5070>,
			<8554 7560 5803 5192 5078 5070>;
	};

};
